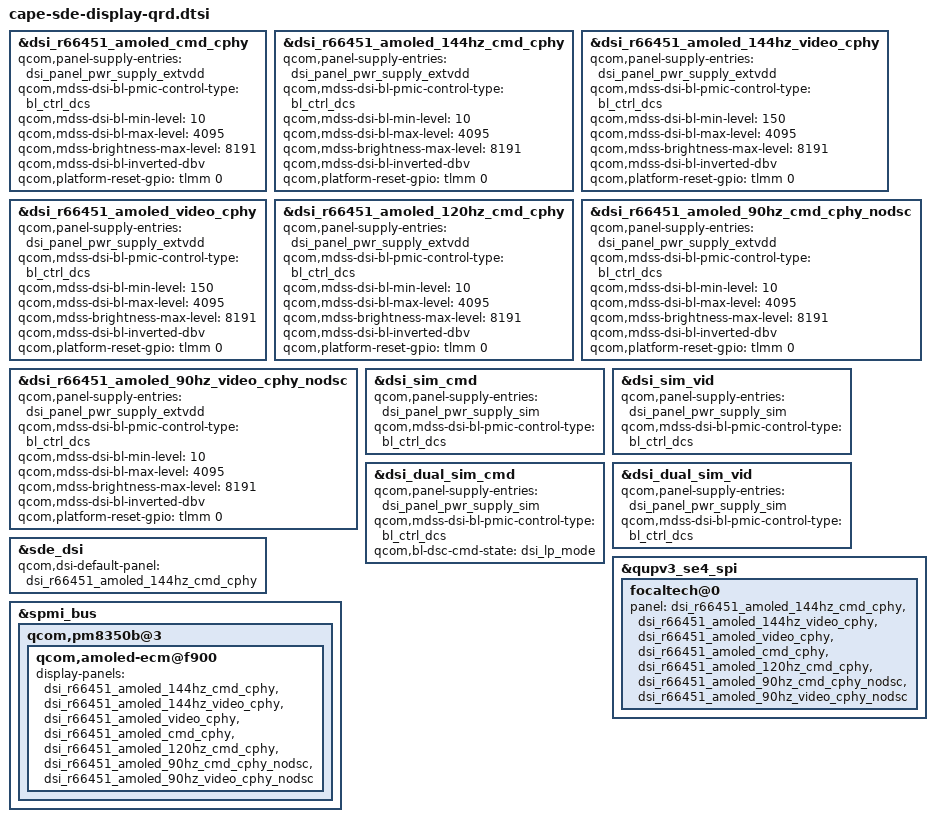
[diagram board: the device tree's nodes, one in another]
#include "cape-sde-display.dtsi"

&dsi_r66451_amoled_cmd_cphy {
	qcom,panel-supply-entries = <&dsi_panel_pwr_supply_extvdd>;
	qcom,mdss-dsi-bl-pmic-control-type = "bl_ctrl_dcs";
	qcom,mdss-dsi-bl-min-level = <10>;
	qcom,mdss-dsi-bl-max-level = <4095>;
	qcom,mdss-brightness-max-level = <8191>;
	qcom,mdss-dsi-bl-inverted-dbv;
	qcom,platform-reset-gpio = <&tlmm 0 0>;
};

&dsi_r66451_amoled_144hz_cmd_cphy {
	qcom,panel-supply-entries = <&dsi_panel_pwr_supply_extvdd>;
	qcom,mdss-dsi-bl-pmic-control-type = "bl_ctrl_dcs";
	qcom,mdss-dsi-bl-min-level = <10>;
	qcom,mdss-dsi-bl-max-level = <4095>;
	qcom,mdss-brightness-max-level = <8191>;
	qcom,mdss-dsi-bl-inverted-dbv;
	qcom,platform-reset-gpio = <&tlmm 0 0>;
};

&dsi_r66451_amoled_144hz_video_cphy {
	qcom,panel-supply-entries = <&dsi_panel_pwr_supply_extvdd>;
	qcom,mdss-dsi-bl-pmic-control-type = "bl_ctrl_dcs";
	qcom,mdss-dsi-bl-min-level = <150>;
	qcom,mdss-dsi-bl-max-level = <4095>;
	qcom,mdss-brightness-max-level = <8191>;
	qcom,mdss-dsi-bl-inverted-dbv;
	qcom,platform-reset-gpio = <&tlmm 0 0>;
};

&dsi_r66451_amoled_video_cphy {
	qcom,panel-supply-entries = <&dsi_panel_pwr_supply_extvdd>;
	qcom,mdss-dsi-bl-pmic-control-type = "bl_ctrl_dcs";
	qcom,mdss-dsi-bl-min-level = <150>;
	qcom,mdss-dsi-bl-max-level = <4095>;
	qcom,mdss-brightness-max-level = <8191>;
	qcom,mdss-dsi-bl-inverted-dbv;
	qcom,platform-reset-gpio = <&tlmm 0 0>;
};

&dsi_r66451_amoled_120hz_cmd_cphy {
	qcom,panel-supply-entries = <&dsi_panel_pwr_supply_extvdd>;
	qcom,mdss-dsi-bl-pmic-control-type = "bl_ctrl_dcs";
	qcom,mdss-dsi-bl-min-level = <10>;
	qcom,mdss-dsi-bl-max-level = <4095>;
	qcom,mdss-brightness-max-level = <8191>;
	qcom,mdss-dsi-bl-inverted-dbv;
	qcom,platform-reset-gpio = <&tlmm 0 0>;
};

&dsi_r66451_amoled_90hz_cmd_cphy_nodsc {
	qcom,panel-supply-entries = <&dsi_panel_pwr_supply_extvdd>;
	qcom,mdss-dsi-bl-pmic-control-type = "bl_ctrl_dcs";
	qcom,mdss-dsi-bl-min-level = <10>;
	qcom,mdss-dsi-bl-max-level = <4095>;
	qcom,mdss-brightness-max-level = <8191>;
	qcom,mdss-dsi-bl-inverted-dbv;
	qcom,platform-reset-gpio = <&tlmm 0 0>;
};

&dsi_r66451_amoled_90hz_video_cphy_nodsc {
	qcom,panel-supply-entries = <&dsi_panel_pwr_supply_extvdd>;
	qcom,mdss-dsi-bl-pmic-control-type = "bl_ctrl_dcs";
	qcom,mdss-dsi-bl-min-level = <10>;
	qcom,mdss-dsi-bl-max-level = <4095>;
	qcom,mdss-brightness-max-level = <8191>;
	qcom,mdss-dsi-bl-inverted-dbv;
	qcom,platform-reset-gpio = <&tlmm 0 0>;
};

&dsi_sim_cmd {
	qcom,panel-supply-entries = <&dsi_panel_pwr_supply_sim>;
	qcom,mdss-dsi-bl-pmic-control-type = "bl_ctrl_dcs";
};

&dsi_sim_vid {
	qcom,panel-supply-entries = <&dsi_panel_pwr_supply_sim>;
	qcom,mdss-dsi-bl-pmic-control-type = "bl_ctrl_dcs";
};

&dsi_dual_sim_cmd {
	qcom,panel-supply-entries = <&dsi_panel_pwr_supply_sim>;
	qcom,mdss-dsi-bl-pmic-control-type = "bl_ctrl_dcs";
	qcom,bl-dsc-cmd-state = "dsi_lp_mode";
};

&dsi_dual_sim_vid {
	qcom,panel-supply-entries = <&dsi_panel_pwr_supply_sim>;
	qcom,mdss-dsi-bl-pmic-control-type = "bl_ctrl_dcs";
};

&sde_dsi {
	qcom,dsi-default-panel = <&dsi_r66451_amoled_144hz_cmd_cphy>;
};

&qupv3_se4_spi {
	focaltech@0 {
		panel = <&dsi_r66451_amoled_144hz_cmd_cphy
			&dsi_r66451_amoled_144hz_video_cphy
			&dsi_r66451_amoled_video_cphy
			&dsi_r66451_amoled_cmd_cphy
			&dsi_r66451_amoled_120hz_cmd_cphy
			&dsi_r66451_amoled_90hz_cmd_cphy_nodsc
			&dsi_r66451_amoled_90hz_video_cphy_nodsc>;
	};
};

&spmi_bus {
	qcom,pm8350b@3 {
		qcom,amoled-ecm@f900 {
			display-panels = <&dsi_r66451_amoled_144hz_cmd_cphy
					&dsi_r66451_amoled_144hz_video_cphy
					&dsi_r66451_amoled_video_cphy
					&dsi_r66451_amoled_cmd_cphy
					&dsi_r66451_amoled_120hz_cmd_cphy
					&dsi_r66451_amoled_90hz_cmd_cphy_nodsc
					&dsi_r66451_amoled_90hz_video_cphy_nodsc>;
		};
	};
};
